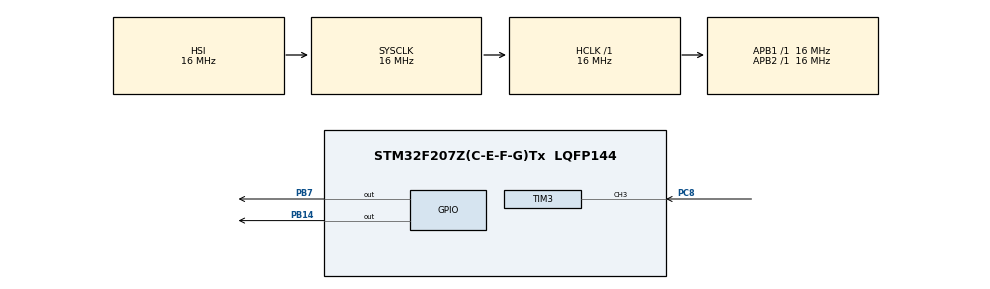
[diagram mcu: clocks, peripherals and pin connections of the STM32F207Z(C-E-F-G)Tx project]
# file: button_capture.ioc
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Mcu.Family=STM32F2
Mcu.Name=STM32F207Z(C-E-F-G)Tx
Mcu.Package=LQFP144
NVIC.PriorityGroup=NVIC_PRIORITYGROUP_4
NVIC.TIM3_IRQn=true\:0\:0\:false\:false\:true\:true\:true\:true
PB14.Signal=GPIO_Output
PB7.Signal=GPIO_Output
PC8.GPIO_PuPd=GPIO_PULLDOWN
PC8.Signal=S_TIM3_CH3
PH0-OSC_IN.Mode=HSE-External-Oscillator
PH0-OSC_IN.Signal=RCC_OSC_IN
PH1-OSC_OUT.Mode=HSE-External-Oscillator
PH1-OSC_OUT.Signal=RCC_OSC_OUT
ProjectManager.HeapSize=0x200
ProjectManager.StackSize=0x400
ProjectManager.TargetToolchain=STM32CubeIDE
RCC.48MHZClocksFreq_Value=48000000
RCC.AHBFreq_Value=16000000
RCC.APB1Freq_Value=16000000
RCC.APB2Freq_Value=16000000
RCC.CortexFreq_Value=16000000
RCC.HSE_VALUE=25000000
RCC.HSI_VALUE=16000000
RCC.LSE_VALUE=32768
RCC.SYSCLKFreq_VALUE=16000000
RCC.VCOOutputFreq_Value=192000000
SH.S_TIM3_CH3.0=TIM3_CH3,Input_Capture3_from_TI3
TIM3.Channel-Input_Capture3_from_TI3=TIM_CHANNEL_3
TIM3.ICPolarity_CH3=TIM_INPUTCHANNELPOLARITY_BOTHEDGE
TIM3.Period=40000 - 1
TIM3.Prescaler=1600 - 1
VP_TIM3_VS_ClockSourceINT.Mode=Internal
board=custom

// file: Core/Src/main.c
/* USER CODE BEGIN Header */
/**
  ******************************************************************************
  * @file           : main.c
  * @brief          : Main program body
  ******************************************************************************
  * @attention
  *
  * Copyright (c) 2023 STMicroelectronics.
  * All rights reserved.
  *
  * This software is licensed under terms that can be found in the LICENSE file
  * in the root directory of this software component.
  * If no LICENSE file comes with this software, it is provided AS-IS.
  *
  ******************************************************************************
  */
/* USER CODE END Header */
#include "main.h"

TIM_HandleTypeDef htim3;

/* USER CODE BEGIN PV */
uint32_t rise = 0;
uint32_t fall = 0;
uint32_t diff = 0;
float time = 0;
/* USER CODE END PV */

void SystemClock_Config(void);
static void MX_GPIO_Init(void);
static void MX_TIM3_Init(void);

/* USER CODE BEGIN 0 */
void HAL_TIM_IC_CaptureCallback(TIM_HandleTypeDef *htim)
{
	static int control = 0;
	if (htim->Channel == HAL_TIM_ACTIVE_CHANNEL_3)
	{
		if (control == 0)
		{
			rise = HAL_TIM_ReadCapturedValue(&htim3, TIM_CHANNEL_3);
			control = 1;
		}
		else
		{
			fall = HAL_TIM_ReadCapturedValue(&htim3, TIM_CHANNEL_3);
			if (fall > rise)
				diff = fall - rise;
			else
				diff = 5000 + fall - rise;
		time = ((((float)diff) / 40000) * 4);
		if (time > 2.0)
			HAL_GPIO_TogglePin(GPIOB, GPIO_PIN_7);
		else
			HAL_GPIO_TogglePin(GPIOB, GPIO_PIN_14);
		control = 0;
		}
	}
}
/* USER CODE END 0 */

int main(void)
{

  /* MCU Configuration--------------------------------------------------------*/

  /* Reset of all peripherals, Initializes the Flash interface and the Systick. */
  HAL_Init();

  /* Configure the system clock */
  SystemClock_Config();

  /* Initialize all configured peripherals */
  MX_GPIO_Init();
  MX_TIM3_Init();
  /* USER CODE BEGIN 2 */
  if (__HAL_TIM_GET_FLAG(&htim3, TIM_FLAG_UPDATE) != RESET)
  __HAL_TIM_CLEAR_FLAG(&htim3, TIM_FLAG_UPDATE);
  HAL_TIM_Base_Start_IT(&htim3);
  HAL_TIM_IC_Start_IT(&htim3, TIM_CHANNEL_3);

  /* USER CODE END 2 */

  /* Infinite loop */
  while (1)
  {

  }
}

void SystemClock_Config(void)
{
  RCC_OscInitTypeDef RCC_OscInitStruct = {0};
  RCC_ClkInitTypeDef RCC_ClkInitStruct = {0};

  /** Initializes the RCC Oscillators according to the specified parameters
  * in the RCC_OscInitTypeDef structure.
  */
  RCC_OscInitStruct.OscillatorType = RCC_OSCILLATORTYPE_HSI;
  RCC_OscInitStruct.HSIState = RCC_HSI_ON;
  RCC_OscInitStruct.HSICalibrationValue = RCC_HSICALIBRATION_DEFAULT;
  RCC_OscInitStruct.PLL.PLLState = RCC_PLL_NONE;
  if (HAL_RCC_OscConfig(&RCC_OscInitStruct) != HAL_OK)
  {
    Error_Handler();
  }

  /** Initializes the CPU, AHB and APB buses clocks
  */
  RCC_ClkInitStruct.ClockType = RCC_CLOCKTYPE_HCLK|RCC_CLOCKTYPE_SYSCLK
                              |RCC_CLOCKTYPE_PCLK1|RCC_CLOCKTYPE_PCLK2;
  RCC_ClkInitStruct.SYSCLKSource = RCC_SYSCLKSOURCE_HSI;
  RCC_ClkInitStruct.AHBCLKDivider = RCC_SYSCLK_DIV1;
  RCC_ClkInitStruct.APB1CLKDivider = RCC_HCLK_DIV1;
  RCC_ClkInitStruct.APB2CLKDivider = RCC_HCLK_DIV1;

  if (HAL_RCC_ClockConfig(&RCC_ClkInitStruct, FLASH_LATENCY_0) != HAL_OK)
  {
    Error_Handler();
  }
}

static void MX_TIM3_Init(void)
{

  TIM_ClockConfigTypeDef sClockSourceConfig = {0};
  TIM_MasterConfigTypeDef sMasterConfig = {0};
  TIM_IC_InitTypeDef sConfigIC = {0};

  htim3.Instance = TIM3;
  htim3.Init.Prescaler = 1600 - 1;
  htim3.Init.CounterMode = TIM_COUNTERMODE_UP;
  htim3.Init.Period = 40000 - 1;
  htim3.Init.ClockDivision = TIM_CLOCKDIVISION_DIV1;
  htim3.Init.AutoReloadPreload = TIM_AUTORELOAD_PRELOAD_DISABLE;
  if (HAL_TIM_Base_Init(&htim3) != HAL_OK)
  {
    Error_Handler();
  }
  sClockSourceConfig.ClockSource = TIM_CLOCKSOURCE_INTERNAL;
  if (HAL_TIM_ConfigClockSource(&htim3, &sClockSourceConfig) != HAL_OK)
  {
    Error_Handler();
  }
  if (HAL_TIM_IC_Init(&htim3) != HAL_OK)
  {
    Error_Handler();
  }
  sMasterConfig.MasterOutputTrigger = TIM_TRGO_RESET;
  sMasterConfig.MasterSlaveMode = TIM_MASTERSLAVEMODE_DISABLE;
  if (HAL_TIMEx_MasterConfigSynchronization(&htim3, &sMasterConfig) != HAL_OK)
  {
    Error_Handler();
  }
  sConfigIC.ICPolarity = TIM_INPUTCHANNELPOLARITY_BOTHEDGE;
  sConfigIC.ICSelection = TIM_ICSELECTION_DIRECTTI;
  sConfigIC.ICPrescaler = TIM_ICPSC_DIV1;
  sConfigIC.ICFilter = 0;
  if (HAL_TIM_IC_ConfigChannel(&htim3, &sConfigIC, TIM_CHANNEL_3) != HAL_OK)
  {
    Error_Handler();
  }

}

static void MX_GPIO_Init(void)
{
  GPIO_InitTypeDef GPIO_InitStruct = {0};

  /* GPIO Ports Clock Enable */
  __HAL_RCC_GPIOH_CLK_ENABLE();
  __HAL_RCC_GPIOB_CLK_ENABLE();
  __HAL_RCC_GPIOC_CLK_ENABLE();

  /*Configure GPIO pin Output Level */
  HAL_GPIO_WritePin(GPIOB, GPIO_PIN_14|GPIO_PIN_7, GPIO_PIN_RESET);

  /*Configure GPIO pins : PB14 PB7 */
  GPIO_InitStruct.Pin = GPIO_PIN_14|GPIO_PIN_7;
  GPIO_InitStruct.Mode = GPIO_MODE_OUTPUT_PP;
  GPIO_InitStruct.Pull = GPIO_NOPULL;
  GPIO_InitStruct.Speed = GPIO_SPEED_FREQ_LOW;
  HAL_GPIO_Init(GPIOB, &GPIO_InitStruct);

}

void Error_Handler(void)
{
  __disable_irq();
  while (1)
  {
  }
}
